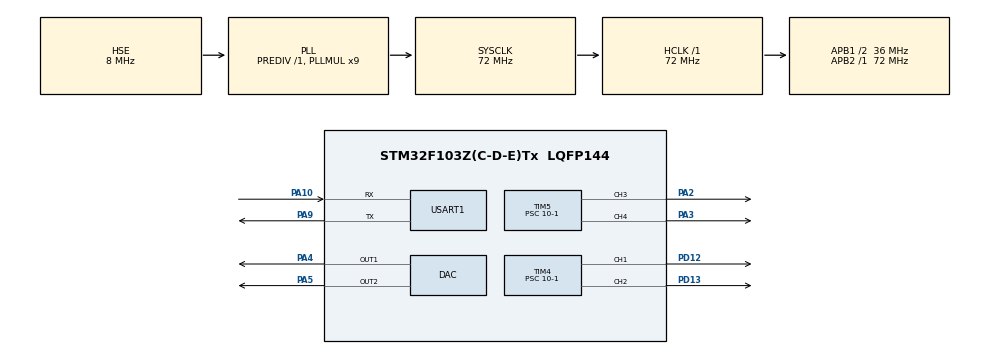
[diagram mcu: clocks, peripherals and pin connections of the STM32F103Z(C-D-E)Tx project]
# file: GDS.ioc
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DAC.DAC_OutputBuffer=DAC_OUTPUTBUFFER_DISABLE
DAC.DAC_OutputBuffer2=DAC_OUTPUTBUFFER_DISABLE
DAC.DAC_Trigger=DAC_TRIGGER_T4_TRGO
DAC.DAC_Trigger2=DAC_TRIGGER_T5_TRGO
Dma.DAC_CH1.2.Direction=DMA_MEMORY_TO_PERIPH
Dma.DAC_CH1.2.Instance=DMA2_Channel3
Dma.DAC_CH1.2.MemDataAlignment=DMA_MDATAALIGN_HALFWORD
Dma.DAC_CH1.2.MemInc=DMA_MINC_ENABLE
Dma.DAC_CH1.2.Mode=DMA_CIRCULAR
Dma.DAC_CH1.2.PeriphDataAlignment=DMA_PDATAALIGN_HALFWORD
Dma.DAC_CH1.2.PeriphInc=DMA_PINC_DISABLE
Dma.DAC_CH1.2.Priority=DMA_PRIORITY_VERY_HIGH
Dma.DAC_CH2.3.Direction=DMA_MEMORY_TO_PERIPH
Dma.DAC_CH2.3.Instance=DMA2_Channel4
Dma.DAC_CH2.3.MemDataAlignment=DMA_MDATAALIGN_HALFWORD
Dma.DAC_CH2.3.MemInc=DMA_MINC_ENABLE
Dma.DAC_CH2.3.Mode=DMA_CIRCULAR
Dma.DAC_CH2.3.PeriphDataAlignment=DMA_PDATAALIGN_HALFWORD
Dma.DAC_CH2.3.PeriphInc=DMA_PINC_DISABLE
Dma.DAC_CH2.3.Priority=DMA_PRIORITY_VERY_HIGH
Dma.Request0=USART1_RX
Dma.Request1=USART1_TX
Dma.Request2=DAC_CH1
Dma.Request3=DAC_CH2
Dma.USART1_RX.0.Direction=DMA_PERIPH_TO_MEMORY
Dma.USART1_RX.0.Instance=DMA1_Channel5
Dma.USART1_RX.0.MemDataAlignment=DMA_MDATAALIGN_BYTE
Dma.USART1_RX.0.MemInc=DMA_MINC_ENABLE
Dma.USART1_RX.0.Mode=DMA_CIRCULAR
Dma.USART1_RX.0.PeriphDataAlignment=DMA_PDATAALIGN_BYTE
Dma.USART1_RX.0.PeriphInc=DMA_PINC_DISABLE
Dma.USART1_RX.0.Priority=DMA_PRIORITY_VERY_HIGH
Dma.USART1_TX.1.Direction=DMA_MEMORY_TO_PERIPH
Dma.USART1_TX.1.Instance=DMA1_Channel4
Dma.USART1_TX.1.MemDataAlignment=DMA_MDATAALIGN_BYTE
Dma.USART1_TX.1.MemInc=DMA_MINC_ENABLE
Dma.USART1_TX.1.Mode=DMA_NORMAL
Dma.USART1_TX.1.PeriphDataAlignment=DMA_PDATAALIGN_BYTE
Dma.USART1_TX.1.PeriphInc=DMA_PINC_DISABLE
Dma.USART1_TX.1.Priority=DMA_PRIORITY_HIGH
FREERTOS.Tasks01=defaultTask,24,128,StartDefaultTask,Default,NULL,Dynamic,NULL,NULL
FREERTOS.configENABLE_FPU=1
FREERTOS.configGENERATE_RUN_TIME_STATS=1
FREERTOS.configRECORD_STACK_HIGH_ADDRESS=1
FREERTOS.configTOTAL_HEAP_SIZE=10240
Mcu.Family=STM32F1
Mcu.Name=STM32F103Z(C-D-E)Tx
Mcu.Package=LQFP144
NVIC.DMA1_Channel4_IRQn=true\:5\:0\:false\:false\:true\:true\:false\:true\:true
NVIC.DMA1_Channel5_IRQn=true\:5\:0\:false\:false\:true\:true\:false\:true\:true
NVIC.DMA2_Channel3_IRQn=true\:5\:0\:false\:false\:true\:true\:false\:true\:true
NVIC.DMA2_Channel4_5_IRQn=true\:5\:0\:false\:false\:true\:true\:false\:true\:true
NVIC.PriorityGroup=NVIC_PRIORITYGROUP_4
NVIC.TIM2_IRQn=true\:15\:0\:false\:false\:true\:false\:false\:true\:true
NVIC.TimeBase=TIM2_IRQn
NVIC.TimeBaseIP=TIM2
NVIC.USART1_IRQn=true\:5\:0\:false\:false\:true\:true\:true\:true\:true
OSC_IN.Mode=HSE-External-Oscillator
OSC_IN.Signal=RCC_OSC_IN
OSC_OUT.Mode=HSE-External-Oscillator
OSC_OUT.Signal=RCC_OSC_OUT
PA10.Mode=Asynchronous
PA10.Signal=USART1_RX
PA13.Mode=Serial_Wire
PA13.Signal=SYS_JTMS-SWDIO
PA14.Mode=Serial_Wire
PA14.Signal=SYS_JTCK-SWCLK
PA2.GPIO_Speed=GPIO_SPEED_FREQ_HIGH
PA2.Signal=S_TIM5_CH3
PA3.GPIO_Speed=GPIO_SPEED_FREQ_HIGH
PA3.Signal=S_TIM5_CH4
PA4.Signal=COMP_DAC1_group
PA5.Signal=COMP_DAC2_group
PA9.Mode=Asynchronous
PA9.Signal=USART1_TX
PD12.GPIO_Speed=GPIO_SPEED_FREQ_HIGH
PD12.Signal=S_TIM4_CH1
PD13.GPIO_Speed=GPIO_SPEED_FREQ_HIGH
PD13.Signal=S_TIM4_CH2
ProjectManager.HeapSize=0x0800
ProjectManager.StackSize=0x1000
ProjectManager.TargetToolchain=CMake
RCC.AHBFreq_Value=72000000
RCC.APB1CLKDivider=RCC_HCLK_DIV2
RCC.APB1Freq_Value=36000000
RCC.APB1TimFreq_Value=72000000
RCC.APB2Freq_Value=72000000
RCC.APB2TimFreq_Value=72000000
RCC.HCLKFreq_Value=72000000
RCC.PLLMUL=RCC_PLL_MUL9
RCC.PLLSourceVirtual=RCC_PLLSOURCE_HSE
RCC.SYSCLKFreq_VALUE=72000000
RCC.SYSCLKSource=RCC_SYSCLKSOURCE_PLLCLK
RCC.USBFreq_Value=48000000
RCC.USBPrescaler=RCC_USBCLKSOURCE_PLL_DIV1_5
SH.COMP_DAC1_group.0=DAC_OUT1,DAC_OUT1
SH.COMP_DAC2_group.0=DAC_OUT2,DAC_OUT2
SH.S_TIM4_CH1.0=TIM4_CH1,PWM Generation1 CH1
SH.S_TIM4_CH2.0=TIM4_CH2,PWM Generation2 CH2
SH.S_TIM5_CH3.0=TIM5_CH3,PWM Generation3 CH3
SH.S_TIM5_CH4.0=TIM5_CH4,PWM Generation4 CH4
TIM4.AutoReloadPreload=TIM_AUTORELOAD_PRELOAD_ENABLE
TIM4.Channel-PWM\ Generation1\ CH1=TIM_CHANNEL_1
TIM4.Channel-PWM\ Generation2\ CH2=TIM_CHANNEL_2
TIM4.Period=720-1
TIM4.Prescaler=10-1
TIM4.Pulse-PWM\ Generation1\ CH1=10
TIM4.Pulse-PWM\ Generation2\ CH2=10
TIM4.TIM_MasterOutputTrigger=TIM_TRGO_UPDATE
TIM5.AutoReloadPreload=TIM_AUTORELOAD_PRELOAD_ENABLE
TIM5.Channel-PWM\ Generation3\ CH3=TIM_CHANNEL_3
TIM5.Channel-PWM\ Generation4\ CH4=TIM_CHANNEL_4
TIM5.Period=720-1
TIM5.Prescaler=10-1
TIM5.Pulse-PWM\ Generation3\ CH3=10
TIM5.Pulse-PWM\ Generation4\ CH4=10
TIM5.TIM_MasterOutputTrigger=TIM_TRGO_UPDATE
USART1.VirtualMode=VM_ASYNC
VP_FREERTOS_VS_CMSIS_V2.Mode=CMSIS_V2
VP_SYS_VS_tim2.Mode=TIM2
VP_TIM4_VS_ClockSourceINT.Mode=Internal
VP_TIM5_VS_ClockSourceINT.Mode=Internal
board=custom

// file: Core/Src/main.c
/* USER CODE BEGIN Header */
/**
  ******************************************************************************
  * @file           : main.c
  * @brief          : Main program body
  ******************************************************************************
  * @attention
  *
  * Copyright (c) 2026 STMicroelectronics.
  * All rights reserved.
  *
  * This software is licensed under terms that can be found in the LICENSE file
  * in the root directory of this software component.
  * If no LICENSE file comes with this software, it is provided AS-IS.
  *
  ******************************************************************************
  */
/* USER CODE END Header */
#include "main.h"
#include "cmsis_os.h"
#include "dac.h"
#include "dma.h"
#include "tim.h"
#include "usart.h"
#include "gpio.h"

/* USER CODE BEGIN Includes */
#include "GDS.hpp"
/* USER CODE END Includes */

void SystemClock_Config(void);
void MX_FREERTOS_Init(void);

int main(void)
{

  /* MCU Configuration--------------------------------------------------------*/

  /* Reset of all peripherals, Initializes the Flash interface and the Systick. */
  HAL_Init();

  /* Configure the system clock */
  SystemClock_Config();

  /* Initialize all configured peripherals */
  MX_GPIO_Init();
  MX_DMA_Init();
  MX_DAC_Init();
  MX_USART1_UART_Init();
  MX_TIM4_Init();
  MX_TIM5_Init();
  /* USER CODE BEGIN 2 */
  initGDSBsp();
  /* USER CODE END 2 */

  /* Init scheduler */
  osKernelInitialize();  /* Call init function for freertos objects (in cmsis_os2.c) */
  MX_FREERTOS_Init();

  /* Start scheduler */
  osKernelStart();

  /* We should never get here as control is now taken by the scheduler */

  /* Infinite loop */
  while (1)
  {

  }
}

void SystemClock_Config(void)
{
  RCC_OscInitTypeDef RCC_OscInitStruct = {0};
  RCC_ClkInitTypeDef RCC_ClkInitStruct = {0};

  /** Initializes the RCC Oscillators according to the specified parameters
  * in the RCC_OscInitTypeDef structure.
  */
  RCC_OscInitStruct.OscillatorType = RCC_OSCILLATORTYPE_HSE;
  RCC_OscInitStruct.HSEState = RCC_HSE_ON;
  RCC_OscInitStruct.HSEPredivValue = RCC_HSE_PREDIV_DIV1;
  RCC_OscInitStruct.HSIState = RCC_HSI_ON;
  RCC_OscInitStruct.PLL.PLLState = RCC_PLL_ON;
  RCC_OscInitStruct.PLL.PLLSource = RCC_PLLSOURCE_HSE;
  RCC_OscInitStruct.PLL.PLLMUL = RCC_PLL_MUL9;
  if (HAL_RCC_OscConfig(&RCC_OscInitStruct) != HAL_OK)
  {
    Error_Handler();
  }

  /** Initializes the CPU, AHB and APB buses clocks
  */
  RCC_ClkInitStruct.ClockType = RCC_CLOCKTYPE_HCLK|RCC_CLOCKTYPE_SYSCLK
                              |RCC_CLOCKTYPE_PCLK1|RCC_CLOCKTYPE_PCLK2;
  RCC_ClkInitStruct.SYSCLKSource = RCC_SYSCLKSOURCE_PLLCLK;
  RCC_ClkInitStruct.AHBCLKDivider = RCC_SYSCLK_DIV1;
  RCC_ClkInitStruct.APB1CLKDivider = RCC_HCLK_DIV2;
  RCC_ClkInitStruct.APB2CLKDivider = RCC_HCLK_DIV1;

  if (HAL_RCC_ClockConfig(&RCC_ClkInitStruct, FLASH_LATENCY_2) != HAL_OK)
  {
    Error_Handler();
  }
}

void HAL_TIM_PeriodElapsedCallback(TIM_HandleTypeDef *htim)
{
  if (htim->Instance == TIM2)
  {
    HAL_IncTick();
  }
}

void Error_Handler(void)
{
  __disable_irq();
  while (1)
  {
  }
}
